AUTOSAR XML (schema 00046)
package /ComponentTypes
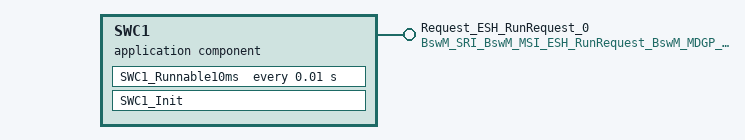
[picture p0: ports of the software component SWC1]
  application sw component type SWC1
    provide port Request_ESH_RunRequest_0: nonqueued-sender-com-spec=requestedMode, provided-interface=BswM_SRI_BswM_MSI_ESH_RunRequest_BswM_MDGP_ESH_RunRequest
    behavior SWC1_InternalBehavior
      init event SWC1_InitEvent: start-on-event=SWC1_Init
      timing event TMT_SWC1_Runnable10ms: start-on-event=SWC1_Runnable10ms, period=0.01
      runnable SWC1_Init
        data-send-points:
          access SEND_Request_ESH_RunRequest_0_requestedMode: accessed-variable=Request_ESH_RunRequest_0.requestedMode
      runnable SWC1_Runnable10ms
  swc implementation SWC1_Implementation: behavior=SWC1_InternalBehavior
